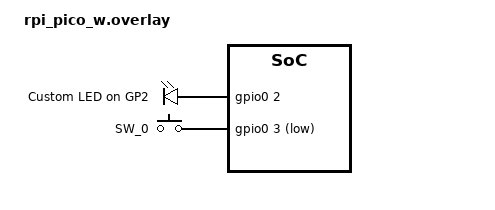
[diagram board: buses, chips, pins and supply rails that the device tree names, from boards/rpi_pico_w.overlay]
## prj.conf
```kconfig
# Logging, minimum without colors
CONFIG_LOG=y
CONFIG_LOG_MODE_MINIMAL=y

# GPIO driver 
CONFIG_GPIO=y

# INPUT API driver 
CONFIG_INPUT=y
```

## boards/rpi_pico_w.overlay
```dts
#include <zephyr/dt-bindings/input/input-event-codes.h>

/ {
    aliases {
        led0 = &my_custom_led;
    };

    leds {
        compatible = "gpio-leds";

        my_custom_led: led_2 {
            /* Map to GP2 on the RP2040 (gpio0 is the main GPIO controller) */
            gpios = <&gpio0 2 GPIO_ACTIVE_HIGH>;
            label = "Custom LED on GP2";
        };
    };

    gpio_keys {
		compatible = "gpio-keys";

		user_btn: button_0 {
			label = "SW_0";
			gpios = <&gpio0 3 (GPIO_PULL_UP | GPIO_ACTIVE_LOW)>;
			zephyr,code = <INPUT_KEY_0>;
		};
	};
};
```

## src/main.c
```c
/**
 * @file main.c
 * @brief Zephyr application demonstrating button input and LED toggling.
 *
 * This file contains the main application logic for reading a button press
 * via the Zephyr input subsystem and toggling an LED associated with the 
 * led0 devicetree alias.
 */

#include <inttypes.h>
#include <zephyr/drivers/gpio.h>
#include <zephyr/input/input.h>
#include <zephyr/kernel.h>
#include <zephyr/logging/log.h>

LOG_MODULE_REGISTER(main, LOG_LEVEL_INF);

/**
 * @def LED0_NODE
 * @brief Devicetree alias for the LED.
 */
#define LED0_NODE DT_ALIAS(led0)

/**
 * @brief GPIO specification for the LED.
 * 
 * A build error on this line means your board is unsupported.
 * See the sample documentation for information on how to fix this.
 */
static const struct gpio_dt_spec led = GPIO_DT_SPEC_GET(LED0_NODE, gpios);

/**
 * @brief Callback function triggered by input events.
 *
 * This callback listens for button events. Upon a synchronized event, it logs
 * the button code, its state (pressed or released), and the cycle count.
 * It also toggles the state of the LED.
 *
 * @param evt Pointer to the input event structure.
 * @param user_data Optional user data passed to the callback (unused).
 */
static void button_input_cb(struct input_event *evt, void *user_data)
{
	if (evt->sync == 0) {
		return;
	}

	LOG_INF("Button %d %s at %u",
	       evt->code,
	       evt->value ? "pressed" : "released",
	       k_cycle_get_32());

	gpio_pin_toggle_dt(&led);
}

/* Register the input callback */
INPUT_CALLBACK_DEFINE(NULL, button_input_cb, NULL);

/**
 * @brief Main application entry point.
 *
 * Initializes the LED GPIO pin as an active output. If successful, it prompts the 
 * user to press the button and puts the main thread to sleep indefinitely 
 * while the input callback handles events in the background.
 *
 * @return 0 on success or initialization failure.
 */
int main(void)
{
	int ret;
	
	if (!gpio_is_ready_dt(&led)) {
		return 0;
	}

	ret = gpio_pin_configure_dt(&led, GPIO_OUTPUT_ACTIVE);
	if (ret < 0) {
		return 0;
	}

	LOG_INF("Press the button");

	k_sleep(K_FOREVER);

	return 0;
}
```
